# STM32F765BGT6 register map
File version: 1.0
STM32F765BGT6,STM32F765BIT6,STM32F765IGK6,STM32F765IGT6,STM32F765IIK6,STM32F765IIK7,STM32F765IIT6,STM32F765IIT7,STM32F765NGH6,STM32F765NGH7,STM32F765NIH6,STM32F765NIH7,STM32F765VGH6,STM32F765VGH7,STM32F765VGT6,STM32F765VGT7,STM32F765VIH6,STM32F765VIT6,STM32F765ZGT6,STM32F765ZGT7,STM32F765ZIT6,STM32F765ZIT7,STM32F767BGT6,STM32F767BIT6,STM32F767IGK6,STM32F767IGT6,STM32F767IIK6,STM32F767IIT6,STM32F767NGH6,STM32F767NIH6,STM32F767NIH7,STM32F767VGH6,STM32F767VGH7,STM32F767VGT6,STM32F767VGT7,STM32F767VIH6,STM32F767VIH7,STM32F767VIT6,STM32F767VIT7,STM32F767ZGT6,STM32F767ZIT6,STM32F768AIY6,STM32F769AGY6,STM32F769AIY6,STM32F769BGT6,STM32F769BIT6,STM32F769IGT6,STM32F769IIT6,STM32F769NGH6,STM32F769NIH6,STM32F777BIT6,STM32F777IIK6,STM32F777IIK7,STM32F777IIT6,STM32F777IIT7,STM32F777NIH6,STM32F777NIH7,STM32F777VIH6,STM32F777VIH7,STM32F777VIT6,STM32F777VIT7,STM32F777ZIT6,STM32F778AIY6,STM32F779AIY6,STM32F779BIT6,STM32F779IIT6,STM32F779NIH6
Registers are 32-bit, access not given, reset 0x0 unless marked. A register's access mark holds for its fields unless they carry their own. Offsets are from the block's base; lines under a group give offsets from that group; [hi:lo] are bit positions; {n}, {i} and the like mark numbered series; 'fields as' and 'values as' point back to an identical list; <NAME> marks a mode.

## Memory map
0x40000000 TIM2
0x40000400 TIM3
0x40000800 TIM4
0x40000C00 TIM5
0x40001000 TIM6
0x40001400 TIM7
0x40001800 TIM12
0x40001C00 TIM13
0x40002000 TIM14
0x40002400 LPTIM1
0x40002800 RTC
0x40002800 BKP
0x40002C00 WWDG
0x40003000 IWDG
0x40003400 CAN3
0x40003800 SPI2
0x40003C00 SPI3
0x40004000 SPDIFRX
0x40004400 USART2
0x40004800 USART3
0x40004C00 UART4
0x40005000 UART5
0x40005400 I2C1
0x40005800 I2C2
0x40005C00 I2C3
0x40006000 I2C4
0x40006400 CAN1
0x40006800 CAN2
0x40006C00 CEC
0x40007000 PWR
0x40007400 DAC
0x40007800 UART7
0x40007C00 UART8
0x40010000 TIM1
0x40010400 TIM8
0x40011000 USART1
0x40011400 USART6
0x40011C00 SDMMC2
0x40012000 ADC1
0x40012100 ADC2
0x40012300 ADC3
0x40012C00 SDMMC1
0x40013000 SPI1
0x40013400 SPI4
0x40013800 SYSCFG
0x40013C00 EXTI
0x40014000 TIM9
0x40014400 TIM10
0x40014800 TIM11
0x40015000 SPI5
0x40015400 SPI6
0x40015800 SAI1
0x40015C00 SAI2
0x40016800 LTDC
0x40016C00 DSIH
0x40017400 DFSDM1
0x40017800 MDIOS
0x40020000 GPIOA
0x40020400 GPIOB
0x40020800 GPIOC
0x40020C00 GPIOD
0x40021000 GPIOE
0x40021400 GPIOF
0x40021800 GPIOG
0x40021C00 GPIOH
0x40022000 GPIOI
0x40022400 GPIOJ
0x40022800 GPIOK
0x40023000 CRC
0x40023800 RCC
0x40023C00 FLASH
0x40024000 BKPSRAM
0x40026000 DMA1
0x40026400 DMA2
0x40028000 ETH
0x4002B000 DMA2D
0x40040000 USB_OTG_HS
0x50000000 USB_OTG_FS
0x50050000 DCMI
0x50051000 JPEG
0x50060000 CRYP
0x50060400 HASH
0x50060800 RNG
0xA0000000 FMC
0xA0001000 QUADSPICR

## TIM2
Base 0x40000000
0x00 CR1
  [11] UIFREMA, [31:10] s, [9:8] CKD, [7] ARPE, [6:5] CMS, [4] DIR, [3] OPM, [2] URS, [1] UDIS, [0] CEN
0x04 CR2
  [7] TI1S, [6:4] MMS, [3] CCDS, [31:0] s
0x08 SMCR
  [31:17] s, [15] ETP, [14] ECE, [13:12] ETPS, [11:8] ETF, [7] MSM, [6:4] TS, [3] OCCS, [16:0] SMS
0x0C DIER
  [14] TDE, [13] COMDE, [n+8] CC{n}DE (n=1..4), [8] UDE, [6] TIE, [31:5] s, [n] CC{n}IE (n=1..4), [0] UIE
0x10 SR
  [n+8] CC{n}OF (n=1..4), [6] TIF, [31:5] s, [n] CC{n}IF (n=1..4), [0] UIF
0x14 EGR
  [6] TG, [31:5] s, [n] CC{n}G (n=1..4), [0] UG
0x18 CCMR1_OUT
  [31:17] s, [15] OC2CE, [24:12] OC2M, [11] OC2PE, [10] OC2FE, [9:8] CC2S, [7] OC1CE, [16:4] OC1M, [3] OC1PE, [2] OC1FE, [1:0] CC1S
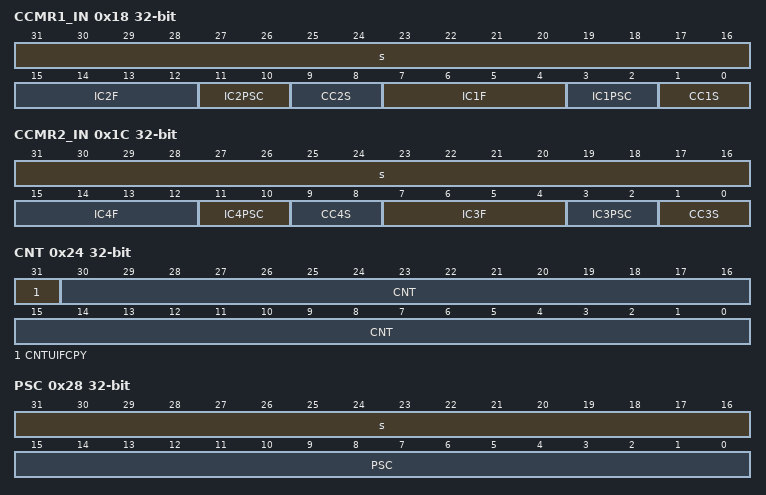
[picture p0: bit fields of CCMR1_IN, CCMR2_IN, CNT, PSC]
0x18 CCMR1_IN
  [31:16] s, [15:12] IC2F, [11:10] IC2PSC, [9:8] CC2S, [7:4] IC1F, [3:2] IC1PSC, [1:0] CC1S
0x1C CCMR2_OUT
  [31:17] s, [15] O24CE, [24:12] OC4M, [11] OC4PE, [10] OC4FE, [9:8] CC4S, [7] OC3CE, [16:4] OC3M, [3] OC3PE, [2] OC3FE, [1:0] CC3S
0x1C CCMR2_IN
  [31:16] s, [15:12] IC4F, [11:10] IC4PSC, [9:8] CC4S, [7:4] IC3F, [3:2] IC3PSC, [1:0] CC3S
0x20 CCER
  [4n-1] CC{n}NP (n=1..4), [4n-3] CC{n}P (n=1..4), [4n-4] CC{n}E (n=1..4), [31:2] s
0x24 CNT
  [31] CNTUIFCPY, [30:0] CNT
0x28 PSC
  [31:16] s, [15:0] PSC
0x2C ARR
{0x30+4i} CCR{i} (i=1..4)
0x48 DCR
  [12:8] DBL, [31:5] s, [4:0] DBA
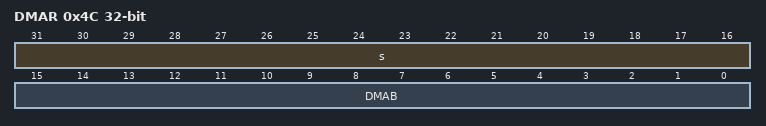
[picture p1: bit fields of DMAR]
0x4C DMAR
  [31:16] s, [15:0] DMAB
0x50 OR
  [11:10] ITR1_RMP, [31:0] s

## TIM3
Base 0x40000400
Registers as TIM2, without OR.

## TIM4
Base 0x40000800
Registers as TIM2, without OR.

## TIM5
Base 0x40000C00
Registers as TIM2; these are added or differ:
0x50 OR
  [7:6] TI4_RMP, [31:0] s
